# STM32MP157 register map
File version: 1.6
CPU: CM4 r0p1, little endian, no MPU, FPU, 4 interrupt priority bits
Registers are 32-bit, read-write, reset 0x0 unless marked. A register's access mark holds for its fields unless they carry their own. Offsets are from the block's base; [hi:lo] are bit positions; {n}, {i} and the like mark numbered series; 'fields as' and 'values as' point back to an identical list.

## DMAMUX1
Base 0x48002000
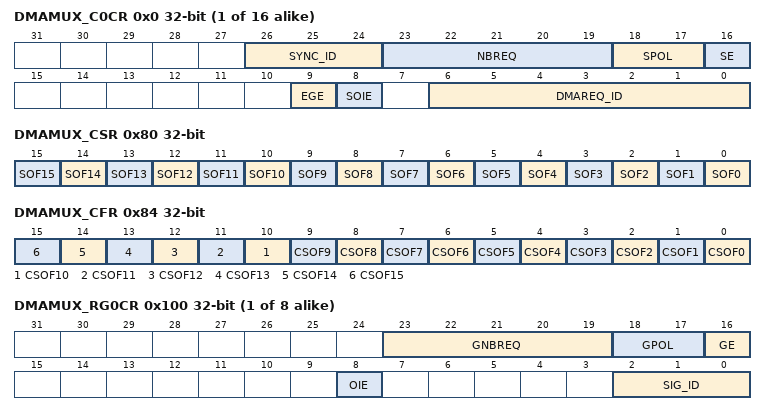
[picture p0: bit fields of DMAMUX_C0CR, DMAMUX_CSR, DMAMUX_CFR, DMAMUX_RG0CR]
{0x0+4i} DMAMUX_C{i}CR (i=0..15) — DMAMUX request line multiplexer channel {i} configuration register
  [26:24] SYNC_ID, [23:19] NBREQ, [18:17] SPOL, [16] SE, [9] EGE, [8] SOIE, [6:0] DMAREQ_ID
0x80 DMAMUX_CSR ro — DMAMUX request line multiplexer interrupt channel status register
  [n] SOF{n} (n=0..15)
0x84 DMAMUX_CFR wo — DMAMUX request line multiplexer interrupt clear flag register
  [n] CSOF{n} (n=0..15)
{0x100+4i} DMAMUX_RG{i}CR (i=0..7) — DMAMUX request generator channel {i} configuration register
  [23:19] GNBREQ, [18:17] GPOL, [16] GE, [8] OIE, [2:0] SIG_ID
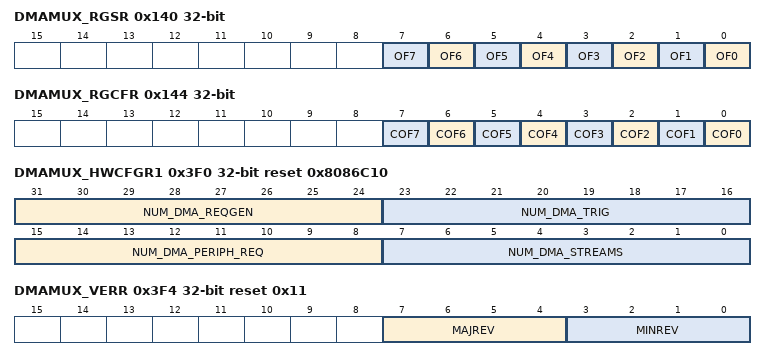
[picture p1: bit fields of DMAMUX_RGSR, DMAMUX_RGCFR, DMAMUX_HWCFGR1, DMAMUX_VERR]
0x140 DMAMUX_RGSR ro — DMAMUX request generator interrupt status register
  [n] OF{n} (n=0..7)
0x144 DMAMUX_RGCFR wo — DMAMUX request generator interrupt clear flag register
  [n] COF{n} (n=0..7)
0x3EC DMAMUX_HWCFGR2 ro reset 0x8 — DMAMUX hardware configuration 2 register
  [7:0] NUM_DMA_EXT_REQ
0x3F0 DMAMUX_HWCFGR1 ro reset 0x8086C10 — DMAMUX hardware configuration 1 register
  [31:24] NUM_DMA_REQGEN, [23:16] NUM_DMA_TRIG, [15:8] NUM_DMA_PERIPH_REQ, [7:0] NUM_DMA_STREAMS
0x3F4 DMAMUX_VERR ro reset 0x11 — This register identifies the IP version.
  [7:4] MAJREV, [3:0] MINREV
0x3F8 DMAMUX_IPIDR ro reset 0x100011 — This register identifies the IP.
  [31:0] ID
0x3FC DMAMUX_SIDR ro reset 0xA3C5DD01 — DMAMUX size identification register
  [31:0] SID

## DTS — DTS register block
Base 0x50028000
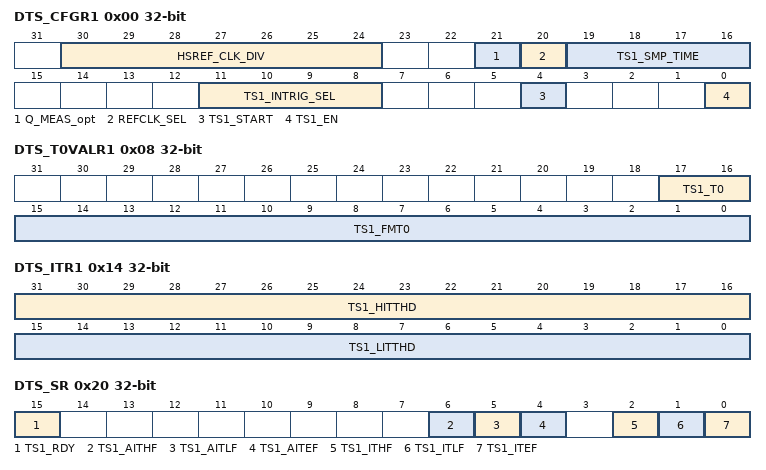
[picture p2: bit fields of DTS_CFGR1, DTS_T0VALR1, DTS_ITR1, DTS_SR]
0x00 DTS_CFGR1 — DTS_CFGR1 is the configuration register for temperature sensor 1.
  [30:24] HSREF_CLK_DIV, [21] Q_MEAS_opt, [20] REFCLK_SEL, [19:16] TS1_SMP_TIME, [11:8] TS1_INTRIG_SEL, [4] TS1_START, [0] TS1_EN
0x08 DTS_T0VALR1 ro — DTS_T0VALR1 contains the value of the factory calibration temperature (T0) for temperature sensor 1. The system reset value is factory trimmed.
  [17:16] TS1_T0, [15:0] TS1_FMT0
0x10 DTS_RAMPVALR ro — The DTS_RAMPVALR is the ramp coefficient for the temperature sensor. The system reset value is factory trimmed.
  [15:0] TS1_RAMP_COEFF
0x14 DTS_ITR1 — DTS_ITR1 contains the threshold values for sensor 1.
  [31:16] TS1_HITTHD, [15:0] TS1_LITTHD
0x1C DTS_DR — The DTS_DR contains the number of REF_CLK cycles used to compute the FM(T) frequency.
  [15:0] TS1_MFREQ
0x20 DTS_SR ro — Temperature sensor status register
  [15] TS1_RDY, [6] TS1_AITHF, [5] TS1_AITLF, [4] TS1_AITEF, [2] TS1_ITHF, [1] TS1_ITLF, [0] TS1_ITEF
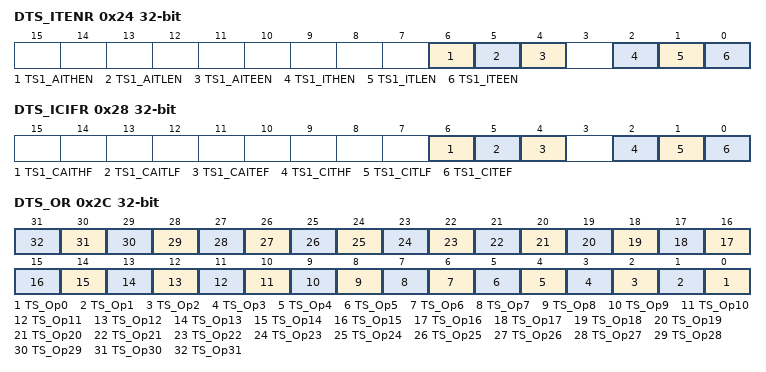
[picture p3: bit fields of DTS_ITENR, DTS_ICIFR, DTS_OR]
0x24 DTS_ITENR — Temperature sensor interrupt enable register
  [6] TS1_AITHEN, [5] TS1_AITLEN, [4] TS1_AITEEN, [2] TS1_ITHEN, [1] TS1_ITLEN, [0] TS1_ITEEN
0x28 DTS_ICIFR — DTS_ICIFR is the control register for the interrupt flags.
  [6] TS1_CAITHF, [5] TS1_CAITLF, [4] TS1_CAITEF, [2] TS1_CITHF, [1] TS1_CITLF, [0] TS1_CITEF
0x2C DTS_OR — The DTS_OR contains general-purpose option bits.
  [n] TS_Op{n} (n=0..31)

## ETH_MTL
Base 0x5800AC00
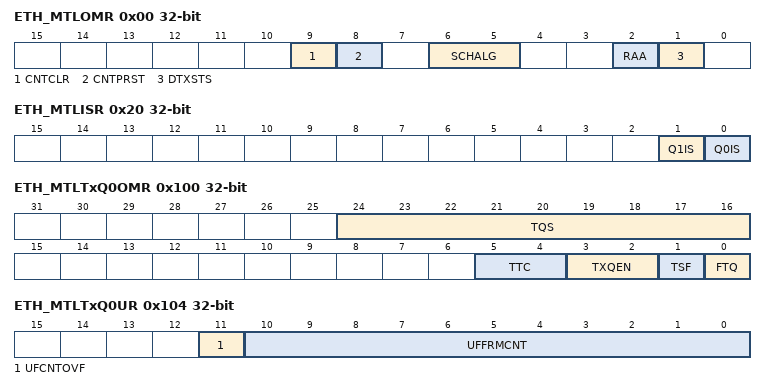
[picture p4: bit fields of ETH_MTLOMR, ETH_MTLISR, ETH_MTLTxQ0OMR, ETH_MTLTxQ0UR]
0x00 ETH_MTLOMR — The Operating Mode register establishes the Transmit and Receive operating modes and commands.
  [9] CNTCLR, [8] CNTPRST, [6:5] SCHALG, [2] RAA, [1] DTXSTS
0x20 ETH_MTLISR ro — The software driver (application) reads this register during interrupt service routine or polling to determine the interrupt status of MTL queues and the MAC.
  [1] Q1IS, [0] Q0IS
0x100 ETH_MTLTxQ0OMR — Tx queue 0 operating mode Register
  [24:16] TQS, [5:4] TTC, [3:2] TXQEN, [1] TSF, [0] FTQ
0x104 ETH_MTLTxQ0UR ro — Tx queue 0 underflow register
  [11] UFCNTOVF, [10:0] UFFRMCNT
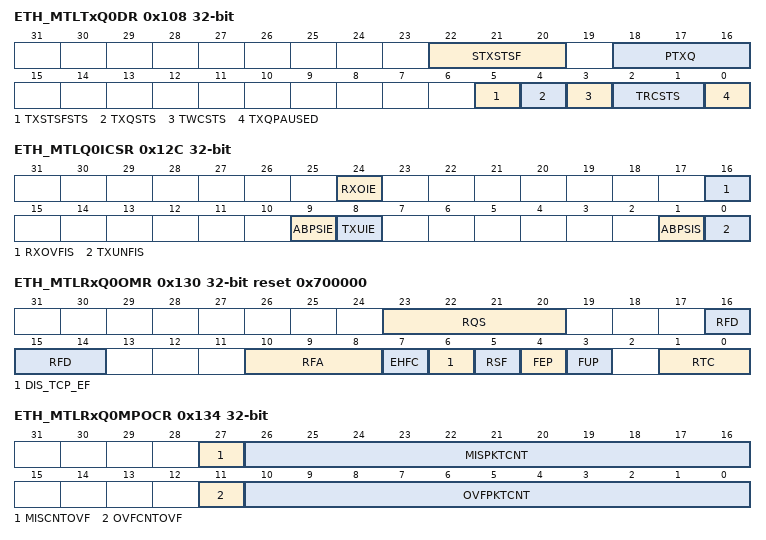
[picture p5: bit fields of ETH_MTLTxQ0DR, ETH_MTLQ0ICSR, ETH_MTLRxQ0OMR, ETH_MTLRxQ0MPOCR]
0x108 ETH_MTLTxQ0DR ro — Tx queue 0 underflow register
  [22:20] STXSTSF, [18:16] PTXQ, [5] TXSTSFSTS, [4] TXQSTS, [3] TWCSTS, [2:1] TRCSTS, [0] TXQPAUSED
0x114 ETH_MTLTxQ0ESR ro — Tx queue x ETS status Register
  [23:0] ABS
0x12C ETH_MTLQ0ICSR — Queue 0 interrupt control status Register
  [24] RXOIE, [16] RXOVFIS, [9] ABPSIE, [8] TXUIE, [1] ABPSIS, [0] TXUNFIS ro
0x130 ETH_MTLRxQ0OMR reset 0x700000 — Rx queue 0 operating mode register
  [23:20] RQS ro, [16:14] RFD, [10:8] RFA, [7] EHFC, [6] DIS_TCP_EF, [5] RSF, [4] FEP, [3] FUP, [1:0] RTC
0x134 ETH_MTLRxQ0MPOCR ro — Rx queue 0 missed packet and overflow counter register
  [27] MISCNTOVF, [26:16] MISPKTCNT, [11] OVFCNTOVF, [10:0] OVFPKTCNT
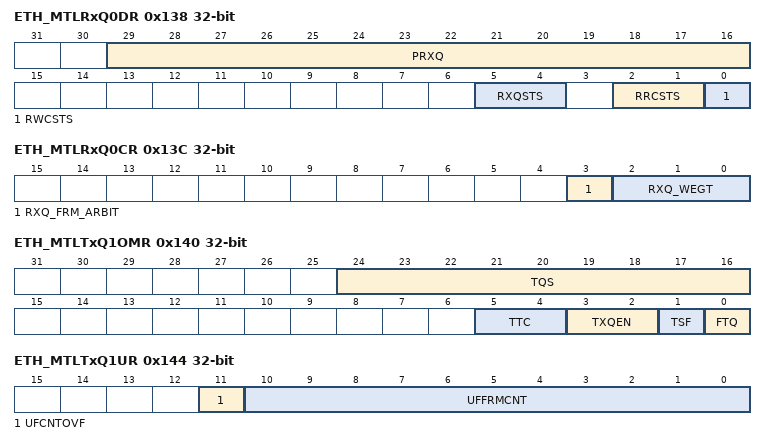
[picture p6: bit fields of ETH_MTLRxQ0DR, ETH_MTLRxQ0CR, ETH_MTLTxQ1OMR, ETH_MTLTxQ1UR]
0x138 ETH_MTLRxQ0DR ro — Rx queue i debug register
  [29:16] PRXQ, [5:4] RXQSTS, [2:1] RRCSTS, [0] RWCSTS
0x13C ETH_MTLRxQ0CR — Rx queue 0 control register
  [3] RXQ_FRM_ARBIT ro, [2:0] RXQ_WEGT ro
0x140 ETH_MTLTxQ1OMR — Tx queue 1 operating mode Register
  [24:16] TQS, [5:4] TTC, [3:2] TXQEN, [1] TSF, [0] FTQ
0x144 ETH_MTLTxQ1UR ro — Tx queue 1 underflow register
  [11] UFCNTOVF, [10:0] UFFRMCNT
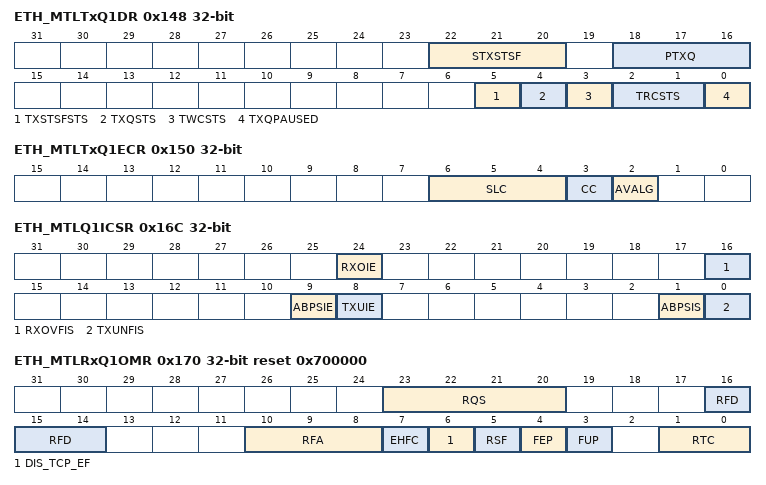
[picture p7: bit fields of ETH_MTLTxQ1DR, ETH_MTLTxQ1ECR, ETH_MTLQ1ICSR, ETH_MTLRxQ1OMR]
0x148 ETH_MTLTxQ1DR ro — Tx queue 1 underflow register
  fields as ETH_MTLTxQ0DR
0x150 ETH_MTLTxQ1ECR — The Queue ETS Control register controls the enhanced transmission selection operation.
  [6:4] SLC, [3] CC, [2] AVALG
0x154 ETH_MTLTxQ1ESR ro — Tx queue x ETS status Register
  [23:0] ABS
0x158 ETH_MTLTxQ1QWR — This register provides the average traffic transmitted on queue 1.
  [20:0] ISCQW
0x15C ETH_MTLTxQ1SSCR — The sendSlopeCredit register contains the sendSlope credit value required for the credit-based shaper algorithm for the Queue.
  [13:0] SSC
0x160 ETH_MTLTxQ1HCR — The hiCredit register contains the hiCredit value required for the credit-based shaper algorithm for the Queue.
  [28:0] HC
0x164 ETH_MTLTxQ1LCR — The loCredit register contains the loCredit value required for the credit-based shaper algorithm for the Queue.
  [28:0] LC
0x16C ETH_MTLQ1ICSR — Queue 1 interrupt control status Register
  fields as ETH_MTLQ0ICSR
0x170 ETH_MTLRxQ1OMR reset 0x700000 — Rx queue 1 operating mode register
  fields as ETH_MTLRxQ0OMR
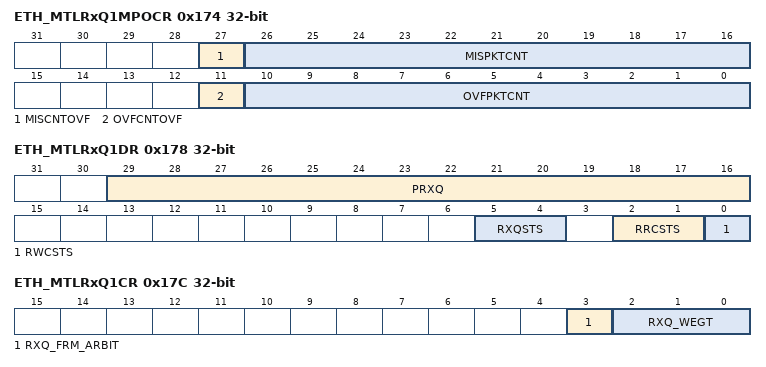
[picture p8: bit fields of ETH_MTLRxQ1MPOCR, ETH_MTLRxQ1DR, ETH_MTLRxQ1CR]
0x174 ETH_MTLRxQ1MPOCR ro — Rx queue 1 missed packet and overflow counter register
  [27] MISCNTOVF, [26:16] MISPKTCNT, [11] OVFCNTOVF, [10:0] OVFPKTCNT
0x178 ETH_MTLRxQ1DR ro — Rx queue i debug register
  [29:16] PRXQ, [5:4] RXQSTS, [2:1] RRCSTS, [0] RWCSTS
0x17C ETH_MTLRxQ1CR — Rx queue 1 control register
  [3] RXQ_FRM_ARBIT ro, [2:0] RXQ_WEGT ro
